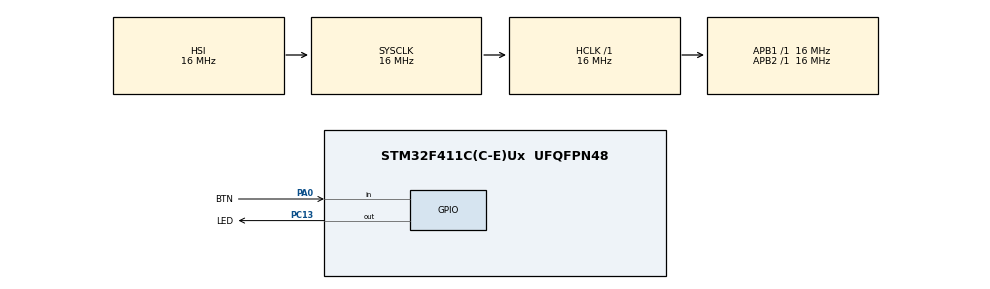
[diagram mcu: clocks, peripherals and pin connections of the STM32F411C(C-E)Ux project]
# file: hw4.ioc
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IWDG.Prescaler=IWDG_PRESCALER_128
IWDG.Reload=2499
Mcu.Family=STM32F4
Mcu.Name=STM32F411C(C-E)Ux
Mcu.Package=UFQFPN48
NVIC.PriorityGroup=NVIC_PRIORITYGROUP_4
PA0-WKUP.GPIO_Label=BTN
PA0-WKUP.Signal=GPIO_Input
PC13-ANTI_TAMP.GPIO_Label=LED
PC13-ANTI_TAMP.Signal=GPIO_Output
ProjectManager.HeapSize=0x200
ProjectManager.StackSize=0x400
ProjectManager.TargetToolchain=Makefile
RCC.AHBFreq_Value=16000000
RCC.APB1Freq_Value=16000000
RCC.APB2Freq_Value=16000000
RCC.CortexFreq_Value=16000000
RCC.HSE_VALUE=25000000
RCC.HSI_VALUE=16000000
RCC.LSE_VALUE=32768
RCC.SYSCLKFreq_VALUE=16000000
RCC.VCOOutputFreq_Value=192000000
VP_IWDG_VS_IWDG.Mode=IWDG_Activate
board=custom

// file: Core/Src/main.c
/* USER CODE BEGIN Header */
/**
  ******************************************************************************
  * @file           : main.c
  * @brief          : Main program body
  ******************************************************************************
  * @attention
  *
  * Copyright (c) 2026 STMicroelectronics.
  * All rights reserved.
  *
  * This software is licensed under terms that can be found in the LICENSE file
  * in the root directory of this software component.
  * If no LICENSE file comes with this software, it is provided AS-IS.
  *
  ******************************************************************************
  */
/* USER CODE END Header */
#include "main.h"
#include "iwdg.h"
#include "gpio.h"

/* USER CODE BEGIN PM */
#define BTN_TICKS 20
/* USER CODE END PM */

void SystemClock_Config(void);

int main(void)
{

  /* MCU Configuration--------------------------------------------------------*/

  /* Reset of all peripherals, Initializes the Flash interface and the Systick. */
  HAL_Init();

  /* Configure the system clock */
  SystemClock_Config();

  /* Initialize all configured peripherals */
  MX_GPIO_Init();
  MX_IWDG_Init();

  /* Infinite loop */
  /* USER CODE BEGIN WHILE */
  uint32_t tick_led = 0;
  uint32_t tick_btn = 0;
  uint32_t blink_period = 200;

  if((HAL_GetTick() - tick_led) > 200) {
    LED_GPIO_Port->BSRR = (uint32_t)LED_Pin;
    tick_led = HAL_GetTick();
  }
  if((HAL_GetTick() - tick_led) > 400) {
    LED_GPIO_Port->BSRR = (uint32_t)LED_Pin << 16;
    tick_led = HAL_GetTick();
  }
  HAL_Delay(1000);

  uint32_t rcc_csr = RCC->CSR;

  RCC->CSR = RCC_CSR_RMVF; //clear the flags
  (void)RCC->CSR;

  if(rcc_csr & RCC_CSR_PINRSTF) { blink_period = 50; } // superfast blinker - PINRSTF is always up after reset - it goes first
  if(rcc_csr & RCC_CSR_IWDGRSTF) { blink_period = 200; } // fast blinker
  if(rcc_csr & RCC_CSR_BORRSTF) { blink_period = 500; } //  slow blinker
  if(rcc_csr & RCC_CSR_PORRSTF) { blink_period = 11000; } // keeps LED on (IWDG resets the MCU in 10s )
  if(rcc_csr & RCC_CSR_SFTRSTF) { blink_period = 0; } // keeps LED OFF

  while (1)
  {
    uint32_t tick = HAL_GetTick();

    if(blink_period) {
      if((tick - tick_led) > blink_period) {
        LED_GPIO_Port->BSRR = (uint32_t)LED_Pin << ((LED_GPIO_Port->ODR & LED_Pin) ? 16 : 0);
        tick_led = tick;
      }
    } else {
      LED_GPIO_Port->BSRR = (uint32_t)LED_Pin;
    }

    if ((tick - tick_btn) > BTN_TICKS) {
      if ((BTN_GPIO_Port->IDR & BTN_Pin) == RESET) {
        NVIC_SystemReset();
      }
    }

    /* USER CODE END WHILE */

  }
}

void SystemClock_Config(void)
{
  RCC_OscInitTypeDef RCC_OscInitStruct = {0};
  RCC_ClkInitTypeDef RCC_ClkInitStruct = {0};

  /** Configure the main internal regulator output voltage
  */
  __HAL_RCC_PWR_CLK_ENABLE();
  __HAL_PWR_VOLTAGESCALING_CONFIG(PWR_REGULATOR_VOLTAGE_SCALE1);

  /** Initializes the RCC Oscillators according to the specified parameters
  * in the RCC_OscInitTypeDef structure.
  */
  RCC_OscInitStruct.OscillatorType = RCC_OSCILLATORTYPE_HSI|RCC_OSCILLATORTYPE_LSI;
  RCC_OscInitStruct.HSIState = RCC_HSI_ON;
  RCC_OscInitStruct.HSICalibrationValue = RCC_HSICALIBRATION_DEFAULT;
  RCC_OscInitStruct.LSIState = RCC_LSI_ON;
  RCC_OscInitStruct.PLL.PLLState = RCC_PLL_NONE;
  if (HAL_RCC_OscConfig(&RCC_OscInitStruct) != HAL_OK)
  {
    Error_Handler();
  }

  /** Initializes the CPU, AHB and APB buses clocks
  */
  RCC_ClkInitStruct.ClockType = RCC_CLOCKTYPE_HCLK|RCC_CLOCKTYPE_SYSCLK
                              |RCC_CLOCKTYPE_PCLK1|RCC_CLOCKTYPE_PCLK2;
  RCC_ClkInitStruct.SYSCLKSource = RCC_SYSCLKSOURCE_HSI;
  RCC_ClkInitStruct.AHBCLKDivider = RCC_SYSCLK_DIV1;
  RCC_ClkInitStruct.APB1CLKDivider = RCC_HCLK_DIV1;
  RCC_ClkInitStruct.APB2CLKDivider = RCC_HCLK_DIV1;

  if (HAL_RCC_ClockConfig(&RCC_ClkInitStruct, FLASH_LATENCY_0) != HAL_OK)
  {
    Error_Handler();
  }
}

void Error_Handler(void)
{
  __disable_irq();
  while (1)
  {
  }
}
